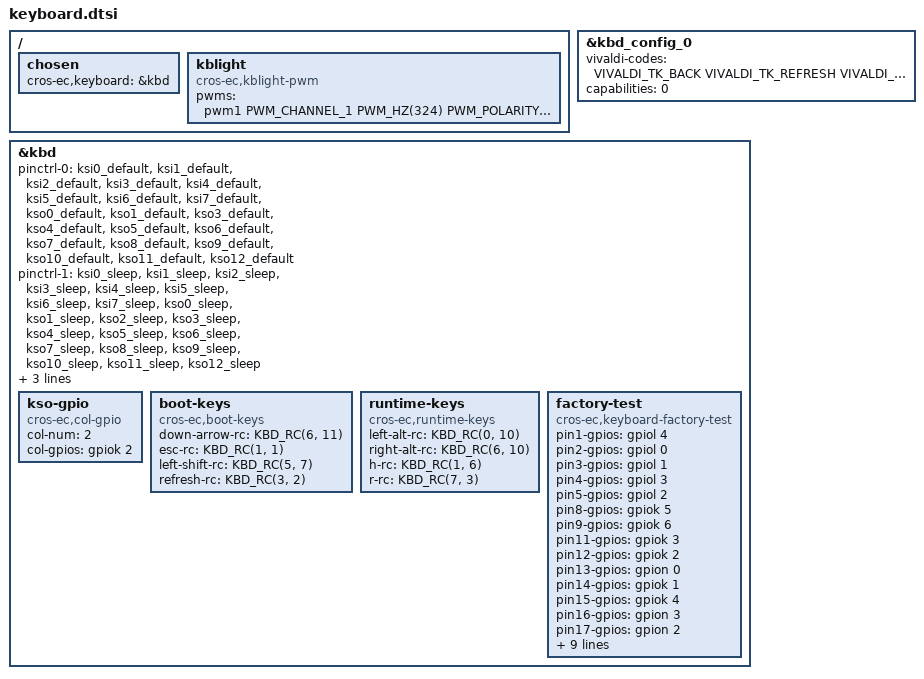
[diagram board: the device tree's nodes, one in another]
/* Copyright 2024 The ChromiumOS Authors
 * Use of this source code is governed by a BSD-style license that can be
 * found in the LICENSE file.
 */

/ {
	chosen {
		cros-ec,keyboard = &kbd;
	};

	kblight: kblight {
		compatible = "cros-ec,kblight-pwm";
		pwms = <&pwm1 PWM_CHANNEL_1 PWM_HZ(324) PWM_POLARITY_NORMAL>;
	};
};

&kbd_config_0 {
	vivaldi-codes = <
		VIVALDI_TK_BACK              /* T1 */
		VIVALDI_TK_REFRESH           /* T2 */
		VIVALDI_TK_FULLSCREEN        /* T3 */
		VIVALDI_TK_OVERVIEW          /* T4 */
		VIVALDI_TK_SNAPSHOT          /* T5 */
		VIVALDI_TK_BRIGHTNESS_DOWN   /* T6 */
		VIVALDI_TK_BRIGHTNESS_UP     /* T7 */
		VIVALDI_TK_VOL_MUTE          /* T8 */
		VIVALDI_TK_VOL_DOWN          /* T9 */
		VIVALDI_TK_VOL_UP            /* T10 */
	>;
	capabilities = <0>;                  /* No lock button */
};

&kbd {
	status = "okay";
	pinctrl-0 = <
		&ksi0_default
		&ksi1_default
		&ksi2_default
		&ksi3_default
		&ksi4_default
		&ksi5_default
		&ksi6_default
		&ksi7_default
		&kso0_default
		&kso1_default
		&kso3_default
		&kso4_default
		&kso5_default
		&kso6_default
		&kso7_default
		&kso8_default
		&kso9_default
		&kso10_default
		&kso11_default
		&kso12_default
	>;
	pinctrl-1 = <
		&ksi0_sleep
		&ksi1_sleep
		&ksi2_sleep
		&ksi3_sleep
		&ksi4_sleep
		&ksi5_sleep
		&ksi6_sleep
		&ksi7_sleep
		&kso0_sleep
		&kso1_sleep
		&kso2_sleep
		&kso3_sleep
		&kso4_sleep
		&kso5_sleep
		&kso6_sleep
		&kso7_sleep
		&kso8_sleep
		&kso9_sleep
		&kso10_sleep
		&kso11_sleep
		&kso12_sleep
	>;
	pinctrl-names = "default", "sleep";
	row-size = <8>;
	col-size = <13>;
	kso-ignore-mask = <04>;

	kso-gpio {
		compatible = "cros-ec,col-gpio";
		col-num = <2>;
		col-gpios = <&gpiok 2 GPIO_ACTIVE_HIGH>;
	};

	boot-keys {
		compatible = "cros-ec,boot-keys";
		down-arrow-rc = <KBD_RC(6, 11)>;
		esc-rc = <KBD_RC(1, 1)>;
		left-shift-rc = <KBD_RC(5, 7)>;
		refresh-rc = <KBD_RC(3, 2)>;
	};

	runtime-keys {
		compatible = "cros-ec,runtime-keys";
		left-alt-rc = <KBD_RC(0, 10)>;
		right-alt-rc = <KBD_RC(6, 10)>;
		h-rc = <KBD_RC(1, 6)>;
		r-rc = <KBD_RC(7, 3)>;
	};

	factory-test {
		compatible = "cros-ec,keyboard-factory-test";

		pin1-gpios = <&gpiol 4 GPIO_ACTIVE_HIGH>;
		pin2-gpios = <&gpiol 0 GPIO_ACTIVE_HIGH>;
		pin3-gpios = <&gpiol 1 GPIO_ACTIVE_HIGH>;
		pin4-gpios = <&gpiol 3 GPIO_ACTIVE_HIGH>;
		pin5-gpios = <&gpiol 2 GPIO_ACTIVE_HIGH>;
		/* 6 nc */
		/* 7 nc */
		pin8-gpios = <&gpiok 5 GPIO_ACTIVE_HIGH>;
		pin9-gpios = <&gpiok 6 GPIO_ACTIVE_HIGH>;
		/* 10 nc */
		pin11-gpios = <&gpiok 3 GPIO_ACTIVE_HIGH>;
		pin12-gpios = <&gpiok 2 GPIO_ACTIVE_HIGH>;
		pin13-gpios = <&gpion 0 GPIO_ACTIVE_HIGH>;
		pin14-gpios = <&gpiok 1 GPIO_ACTIVE_HIGH>;
		pin15-gpios = <&gpiok 4 GPIO_ACTIVE_HIGH>;
		pin16-gpios = <&gpion 3 GPIO_ACTIVE_HIGH>;
		pin17-gpios = <&gpion 2 GPIO_ACTIVE_HIGH>;
		pin18-gpios = <&gpiok 0 GPIO_ACTIVE_HIGH>;
		pin19-gpios = <&gpion 5 GPIO_ACTIVE_HIGH>;
		pin20-gpios = <&gpion 4 GPIO_ACTIVE_HIGH>;
		pin21-gpios = <&gpiok 7 GPIO_ACTIVE_HIGH>;
		pin22-gpios = <&gpion 6 GPIO_ACTIVE_HIGH>;
		pin23-gpios = <&gpion 7 GPIO_ACTIVE_HIGH>;
		pin24-gpios = <&gpion 1 GPIO_ACTIVE_HIGH>;
		/* 25 nc */
		pin26-gpios = <&gpiol 5 GPIO_ACTIVE_HIGH>;
		/* 27 nc */
		pin28-gpios = <&gpiol 6 GPIO_ACTIVE_HIGH>;
	};
};
